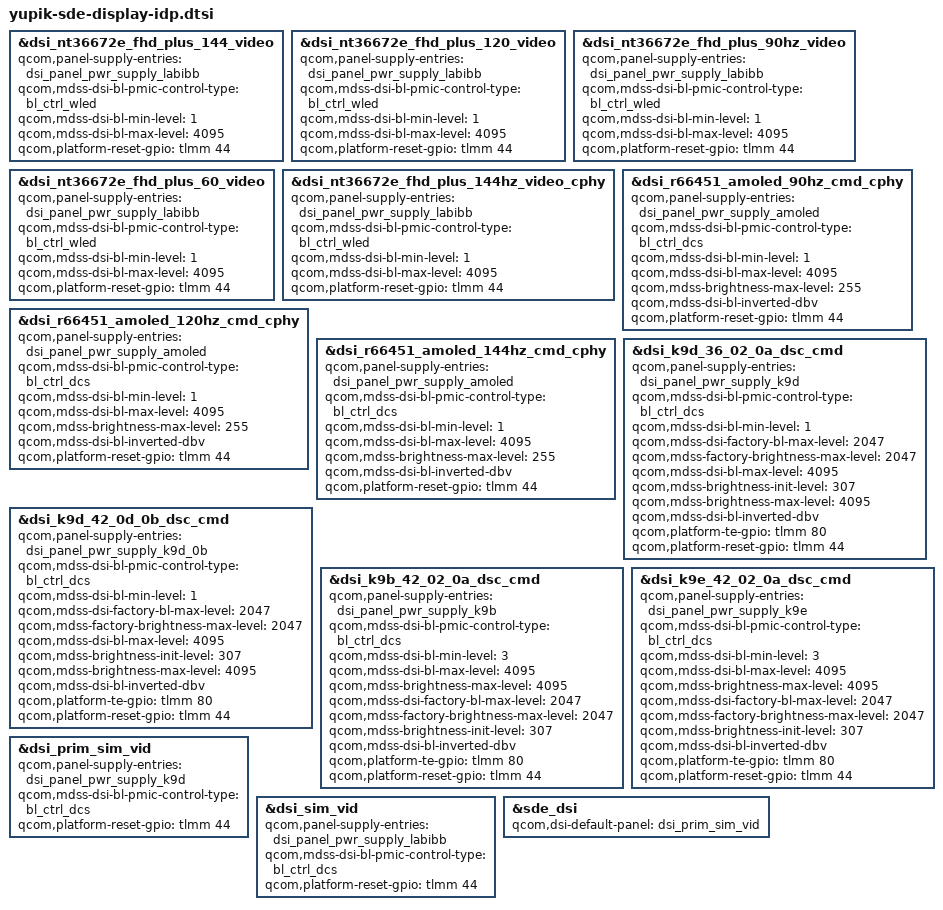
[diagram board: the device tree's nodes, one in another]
#include "yupik-sde-display.dtsi"

&dsi_nt36672e_fhd_plus_144_video {
	qcom,panel-supply-entries = <&dsi_panel_pwr_supply_labibb>;
	qcom,mdss-dsi-bl-pmic-control-type = "bl_ctrl_wled";
	qcom,mdss-dsi-bl-min-level = <1>;
	qcom,mdss-dsi-bl-max-level = <4095>;
	qcom,platform-reset-gpio = <&tlmm 44 0>;
};

&dsi_nt36672e_fhd_plus_120_video {
	qcom,panel-supply-entries = <&dsi_panel_pwr_supply_labibb>;
	qcom,mdss-dsi-bl-pmic-control-type = "bl_ctrl_wled";
	qcom,mdss-dsi-bl-min-level = <1>;
	qcom,mdss-dsi-bl-max-level = <4095>;
	qcom,platform-reset-gpio = <&tlmm 44 0>;
};

&dsi_nt36672e_fhd_plus_90hz_video {
	qcom,panel-supply-entries = <&dsi_panel_pwr_supply_labibb>;
	qcom,mdss-dsi-bl-pmic-control-type = "bl_ctrl_wled";
	qcom,mdss-dsi-bl-min-level = <1>;
	qcom,mdss-dsi-bl-max-level = <4095>;
	qcom,platform-reset-gpio = <&tlmm 44 0>;
};

&dsi_nt36672e_fhd_plus_60_video {
	qcom,panel-supply-entries = <&dsi_panel_pwr_supply_labibb>;
	qcom,mdss-dsi-bl-pmic-control-type = "bl_ctrl_wled";
	qcom,mdss-dsi-bl-min-level = <1>;
	qcom,mdss-dsi-bl-max-level = <4095>;
	qcom,platform-reset-gpio = <&tlmm 44 0>;
};

&dsi_nt36672e_fhd_plus_144hz_video_cphy {
	qcom,panel-supply-entries = <&dsi_panel_pwr_supply_labibb>;
	qcom,mdss-dsi-bl-pmic-control-type = "bl_ctrl_wled";
	qcom,mdss-dsi-bl-min-level = <1>;
	qcom,mdss-dsi-bl-max-level = <4095>;
	qcom,platform-reset-gpio = <&tlmm 44 0>;
};

&dsi_r66451_amoled_90hz_cmd_cphy {
	qcom,panel-supply-entries = <&dsi_panel_pwr_supply_amoled>;
	qcom,mdss-dsi-bl-pmic-control-type = "bl_ctrl_dcs";
	qcom,mdss-dsi-bl-min-level = <1>;
	qcom,mdss-dsi-bl-max-level = <4095>;
	qcom,mdss-brightness-max-level = <255>;
	qcom,mdss-dsi-bl-inverted-dbv;
	qcom,platform-reset-gpio = <&tlmm 44 0>;
};

&dsi_r66451_amoled_120hz_cmd_cphy {
	qcom,panel-supply-entries = <&dsi_panel_pwr_supply_amoled>;
	qcom,mdss-dsi-bl-pmic-control-type = "bl_ctrl_dcs";
	qcom,mdss-dsi-bl-min-level = <1>;
	qcom,mdss-dsi-bl-max-level = <4095>;
	qcom,mdss-brightness-max-level = <255>;
	qcom,mdss-dsi-bl-inverted-dbv;
	qcom,platform-reset-gpio = <&tlmm 44 0>;
};

&dsi_r66451_amoled_144hz_cmd_cphy {
	qcom,panel-supply-entries = <&dsi_panel_pwr_supply_amoled>;
	qcom,mdss-dsi-bl-pmic-control-type = "bl_ctrl_dcs";
	qcom,mdss-dsi-bl-min-level = <1>;
	qcom,mdss-dsi-bl-max-level = <4095>;
	qcom,mdss-brightness-max-level = <255>;
	qcom,mdss-dsi-bl-inverted-dbv;
	qcom,platform-reset-gpio = <&tlmm 44 0>;
};

&dsi_k9d_36_02_0a_dsc_cmd {
	qcom,panel-supply-entries = <&dsi_panel_pwr_supply_k9d>;
	qcom,mdss-dsi-bl-pmic-control-type = "bl_ctrl_dcs";
	qcom,mdss-dsi-bl-min-level = <1>;
	qcom,mdss-dsi-factory-bl-max-level = <2047>;
	qcom,mdss-factory-brightness-max-level = <2047>;
	qcom,mdss-dsi-bl-max-level = <4095>;
	qcom,mdss-brightness-init-level = <307>;
	qcom,mdss-brightness-max-level = <4095>;
	qcom,mdss-dsi-bl-inverted-dbv;
	qcom,platform-te-gpio = <&tlmm 80 0>;
	qcom,platform-reset-gpio = <&tlmm 44 0>;
};

&dsi_k9d_42_0d_0b_dsc_cmd {
	qcom,panel-supply-entries = <&dsi_panel_pwr_supply_k9d_0b>;
	qcom,mdss-dsi-bl-pmic-control-type = "bl_ctrl_dcs";
	qcom,mdss-dsi-bl-min-level = <1>;
	qcom,mdss-dsi-factory-bl-max-level = <2047>;
	qcom,mdss-factory-brightness-max-level = <2047>;
	qcom,mdss-dsi-bl-max-level = <4095>;
	qcom,mdss-brightness-init-level = <307>;
	qcom,mdss-brightness-max-level = <4095>;
	qcom,mdss-dsi-bl-inverted-dbv;
	qcom,platform-te-gpio = <&tlmm 80 0>;
	qcom,platform-reset-gpio = <&tlmm 44 0>;
};

&dsi_k9b_42_02_0a_dsc_cmd {
	qcom,panel-supply-entries = <&dsi_panel_pwr_supply_k9b>;
	qcom,mdss-dsi-bl-pmic-control-type = "bl_ctrl_dcs";
	qcom,mdss-dsi-bl-min-level = <3>;
	qcom,mdss-dsi-bl-max-level = <4095>;
	qcom,mdss-brightness-max-level = <4095>;
	qcom,mdss-dsi-factory-bl-max-level = <2047>;
	qcom,mdss-factory-brightness-max-level = <2047>;
	qcom,mdss-brightness-init-level = <307>;
	qcom,mdss-dsi-bl-inverted-dbv;
	qcom,platform-te-gpio = <&tlmm 80 0>;
	qcom,platform-reset-gpio = <&tlmm 44 0>;
};

&dsi_k9e_42_02_0a_dsc_cmd {
	qcom,panel-supply-entries = <&dsi_panel_pwr_supply_k9e>;
	qcom,mdss-dsi-bl-pmic-control-type = "bl_ctrl_dcs";
	qcom,mdss-dsi-bl-min-level = <3>;
	qcom,mdss-dsi-bl-max-level = <4095>;
	qcom,mdss-brightness-max-level = <4095>;
	qcom,mdss-dsi-factory-bl-max-level = <2047>;
	qcom,mdss-factory-brightness-max-level = <2047>;
	qcom,mdss-brightness-init-level = <307>;
	qcom,mdss-dsi-bl-inverted-dbv;
	qcom,platform-te-gpio = <&tlmm 80 0>;
	qcom,platform-reset-gpio = <&tlmm 44 0>;
};

&dsi_prim_sim_vid {
	qcom,panel-supply-entries = <&dsi_panel_pwr_supply_k9d>;
	qcom,mdss-dsi-bl-pmic-control-type = "bl_ctrl_dcs";
	qcom,platform-reset-gpio = <&tlmm 44 0>;
};

&dsi_sim_vid {
	qcom,panel-supply-entries = <&dsi_panel_pwr_supply_labibb>;
	qcom,mdss-dsi-bl-pmic-control-type = "bl_ctrl_dcs";
	qcom,platform-reset-gpio = <&tlmm 44 0>;
};

&sde_dsi {
	qcom,dsi-default-panel = <&dsi_prim_sim_vid>;
};

